# M55M1 register map
File version: 1.0
Registers are 32-bit, read-write, reset 0x0 unless marked. A register's access mark holds for its fields unless they carry their own. Offsets are from the block's base; [hi:lo] are bit positions; {n}, {i} and the like mark numbered series; 'fields as' and 'values as' point back to an identical list.

## FMC_NSBA — FMC Register Map
Base 0x50044000
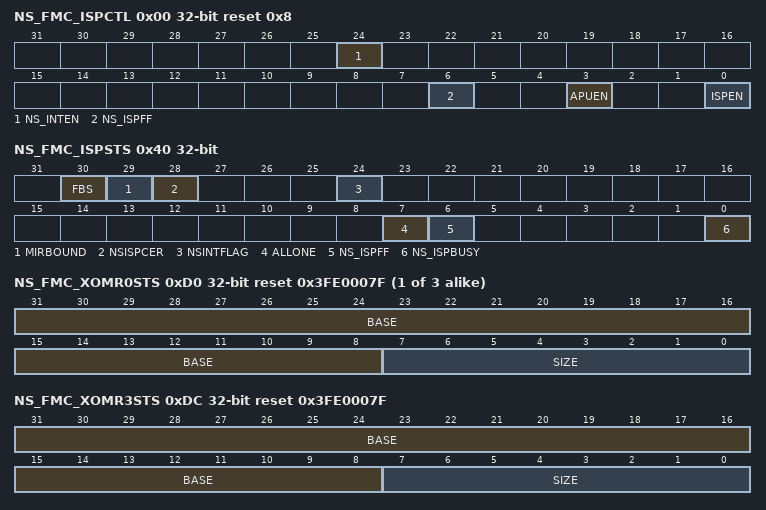
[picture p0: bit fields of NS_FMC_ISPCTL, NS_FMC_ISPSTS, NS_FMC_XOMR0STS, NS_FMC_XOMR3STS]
0x00 NS_FMC_ISPCTL reset 0x8 — Non-secure ISP Control Register
  [24] NS_INTEN — Non-secure ISP interrupt Enable Bit. Note: This bit is write protected. Refer to the SYS_REGLCTL register. Before using INT, user needs to clear the INTFLAG(FMC_ISPSTS[24]) make sure INT happen at correct time.
    0=NS_ISP INT Disabled; 1=NS_ISP INT Enabled
  [6] NS_ISPFF — Non-sec ISP Fail Flag (Write Protect). This bit is set by hardware when a triggered ISP meets any of the following conditions: This bit needs to be cleared by writing 1 to it. APROM writes to itself if APUEN is set to 0. Page Erase command at LOCK mode with ICE connection. Erase or Program command at brown-out detected. Destination address is illegal, such as over an available range. Invalid ISP commands. Read any content of boot loader with ICE connection. ISP CMD in XOM region, except xom page erase and chksum command. The wrong setting of page erase ISP CMD in XOM. Violate XOM setting one time protection. Page erase ISP CMD in Secure region setting page. Page erase, mass erase, multi-word program or 64-bit word program in OTP. NS_ISP Conflict Error. Note: This bit is write protected. Refer to the SYS_REGLCTL register.
  [3] APUEN — APROM Update Enable Bit (Write Protect). Note: This bit is write protected. Refer to the SYS_REGLCTL register.
    0=APROM cannot be updated when the chip runs in APROM; 1=APROM can be updated when the chip runs in APROM
  [0] ISPEN — ISP Enable Bit (Write Protect). ISP function enable. Note: This bit is read only to show ISP function enable.
    1=ISP function Enabled
0x04 NS_FMC_ISPADDR — Non-secure ISP Address Register
  [31:0] NS_ISPADDR — Non-sec ISP Address. The M55 series is equipped with embedded Flash. ISPADDR[1:0] must be kept 00 for ISP 32-bit operation. For CRC32 Checksum Calculation command, this field is the Flash starting address for checksum calculation, 8 Kbytes alignment is necessary for CRC32 checksum calculation. For Flash32-bit Program, ISP address needs word alignment (4-byte). For Flash 64-bit Program, ISP address needs double word alignment (8-byte). Non-sec ISP address must be active at Non-sec region.
0x08 NS_FMC_ISPDAT — Non-secure ISP Data Register
  [31:0] NS_ISPDAT — Non-sec ISP Data. Write data to this register before ISP program operation. Read data from this register after ISP read operation.
0x0C NS_FMC_ISPCMD — Non-secure ISP Command Register
  [6:0] NS_CMD — Non-sec ISP Command. ISP command table is shown below: The other commands are invalid.
    0=FLASH Read; 4=Read Unique ID; 8=Read Flash All-One Result; 11=Read Company ID; 12=Read Device ID; 13=Read Checksum; 33=FLASH 32-bit Program; 34=FLASH Page Erase. Erase only non-secure page in two banks; 40=Run Flash All-One Verification; 45=Run Checksum Calculation
0x10 NS_FMC_ISPTRG — Non-secure ISP Trigger Control Register
  [0] NS_ISPGO — Non-sec ISP Start Trigger (Write Protect). Note: This bit is write protected. Refer to the SYS_REGLCTL register.
    0=ISP operation is finished; 1=ISP is progressed
0x40 NS_FMC_ISPSTS — Non-secure ISP Status Register
  [30] FBS ro — Flash Bank Selection (Read Only). This bit indicate which bank is selected to boot.
    0=Booting from BANK0; 1=Booting from BANK1
  [29] MIRBOUND ro — Mirror Boundary (Read Only)
    0=Mirror Boundary Disabled; 1=Mirror Boundary Enabled
  [28] NSISPCER — Non-secure ISP Conflict Error. This bit shows when FMC is doing ISP operation. User cannot access NS_FMC_ISP_ADDR,NS_FMC_ISPDAT,NS_FMC_ISPCMD,NS_FMC_ISPTRG. It would cause ISPFF.
  [24] NSINTFLAG — Non-sec ISP interrupt Flag. Note: This function needs to be enabled by Non-secure FMC_ISPCTRL[24].
    0=ISP Not Finished; 1=ISP done or ISPFF set
  [7] ALLONE — Flash All-one Verification Flag. This bit is set by hardware if all of Flash bits are 1, and cleared if Flash bits are not all 1 after 'Run Flash All-One Verification' is complete; this bit also can be cleared by writing 1
    0=Flash bits are not all 1 after 'Run Flash All-One Verification' complete; 1=All of Flash bits are 1 after 'Run Flash All-One Verification' complete
  [6] NS_ISPFF — Non-sec ISP Fail Flag (Write Protect). This bit is set by hardware when a triggered ISP meets any of the following conditions: This bit needs to be cleared by writing 1 to it. APROM writes to itself if APUEN is set to 0. Page Erase command at LOCK mode with ICE connection. Erase or Program command at brown-out detected. Destination address is illegal, such as over an available range. Invalid ISP commands. Read any content of boot loader with ICE connection. ISP CMD in XOM region, except XOM page erase and chksum command. The wrong setting of page erase ISP CMD in XOM. Violate XOM setting one time protection. Page erase ISP CMD in Secure region setting page. Page erase, mass erase, multi-word program or 64-bit word program in OTP. Note: This bit is write protected. Refer to the SYS_REGLCTL register.
  [0] NS_ISPBUSY ro — Non-sec ISP Busy Flag (Read Only). Write 1 to start ISP operation and this bit will be cleared to 0 by hardware automatically when ISP operation is finished. This bit is the mirror of ISPGO(FMC_ISPTRG[0]).
    0=ISP operation is finished; 1=ISP is progressed
{0xD0+4i} NS_FMC_XOMR{i}STS ro reset 0x3FE0007F (i=0..2) — Non-secure XOM Region {i} Status Register
  [31:8] BASE — XOM Region {i} Base Address. BASE is the base address of XOM Region {i}. Note: The base address is page aligned.
  [7:0] SIZE — XOM Region {i} Size. SIZE is the page number of XOM Region {i}.
0xDC NS_FMC_XOMR3STS ro reset 0x3FE0007F — Non-secure XOM Region 3 Status Register
  [31:8] BASE — XOM Region 3 Base Address. BASE is the base address of XOM Region 3. Note: The base address is page aligned.
  [7:0] SIZE — XOM Region 3 Size. SIZE is the page number of XOM Region 3. Note: The base address is page aligned.
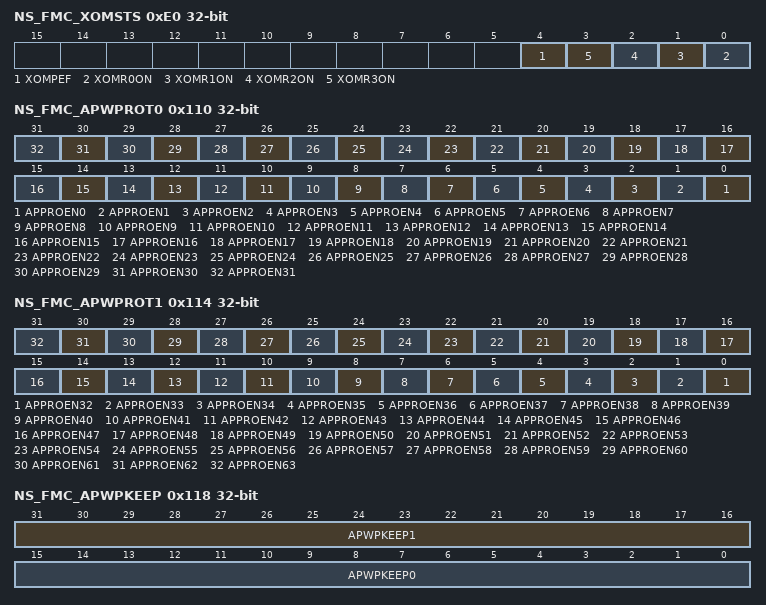
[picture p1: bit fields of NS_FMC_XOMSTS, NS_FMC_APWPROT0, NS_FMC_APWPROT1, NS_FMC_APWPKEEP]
0xE0 NS_FMC_XOMSTS ro — Non-secure XOM Status Register
  [4] XOMPEF — XOM Page Erase Function Fail. XOM page erase function status. If XOMPEF is set to 1, user needs to erase XOM region again.
    0=Success; 1=Fail
  [n] XOMR{n}ON (n=0..3) — XOM Region {n} On. XOM Region {n} active status.
    0=Not active; 1=XOM region {n} is active
0x110 NS_FMC_APWPROT0 ro — APROM Write Protect Register0
  [all] fields
    0=APROM region n is not protected; 1=APROM region n is protected
  [n] APPROEN{n} (n=0..31) — APROM Proect enable. This bit indicates which APROM region is protected. Note: APROM protect region is 0x1010_0000 + n*(0x8000) to 0x1010_7fff + n*(0x8000)
0x114 NS_FMC_APWPROT1 ro — APROM Write Protect Register1
  [all] fields
    values as the fields of NS_FMC_APWPROT0
  [n-32] APPROEN{n} (n=32..63) — APROM Proect enable. This bit indicates which APROM region is protected. Note: APROM protect region is 0x1020_0000 + n*(0x8000) to 0x1020_7fff + n*(0x8000)
0x118 NS_FMC_APWPKEEP ro — APROM Write Protect Keep Register
  [31:16] APWPKEEP1 — APROM Write Protect Keep 1
    0x55AA=APWPROT1 register is be locked
  [15:0] APWPKEEP0 — APROM Write Protect Keep 0
    0x55AA=APWPROT0 register is be locked
0x11C NS_FMC_SCACT ro — APROM Secure Conceal Active Register
  [0] SCACT — Secure Conceal Function Active. Note: secure conceal function active will base on this bit and setting of CONFIG6 is all 0.
    0=secure conceal function inactive; 1=secure conceal function active
